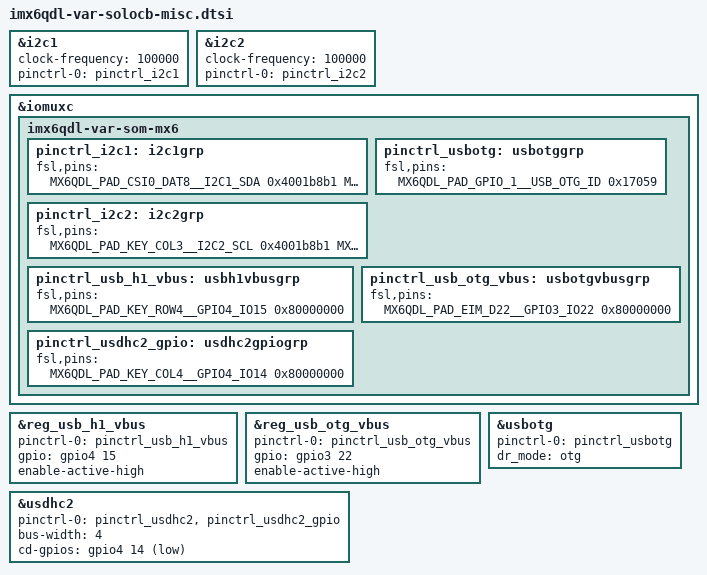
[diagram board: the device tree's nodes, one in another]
/*
 * Copyright (C) 2015-2024 Variscite Ltd.
 *
 * This program is free software; you can redistribute it and/or modify
 * it under the terms of the GNU General Public License version 2 as
 * published by the Free Software Foundation.
 *
 * Settings for VAR-SoloCustomBoard
 */

&i2c1 {
	clock-frequency = <100000>;
	pinctrl-names = "default";
	pinctrl-0 = <&pinctrl_i2c1>;
	status = "okay";
};

&i2c2 {
	clock-frequency = <100000>;
	pinctrl-names = "default";
	pinctrl-0 = <&pinctrl_i2c2>;
	status = "okay";
};

&iomuxc {
	imx6qdl-var-som-mx6 {
		pinctrl_i2c1: i2c1grp {
			fsl,pins = <
				MX6QDL_PAD_CSI0_DAT8__I2C1_SDA		0x4001b8b1
				MX6QDL_PAD_CSI0_DAT9__I2C1_SCL		0x4001b8b1
			>;
		};

		pinctrl_i2c2: i2c2grp {
			fsl,pins = <
				MX6QDL_PAD_KEY_COL3__I2C2_SCL		0x4001b8b1
				MX6QDL_PAD_KEY_ROW3__I2C2_SDA		0x4001b8b1
			>;
		};

		pinctrl_usbotg: usbotggrp {
			fsl,pins = <
				MX6QDL_PAD_GPIO_1__USB_OTG_ID		0x17059
			>;
		};

		pinctrl_usb_h1_vbus: usbh1vbusgrp {
			fsl,pins = <
				MX6QDL_PAD_KEY_ROW4__GPIO4_IO15		0x80000000
			>;
		};

		pinctrl_usb_otg_vbus: usbotgvbusgrp {
			fsl,pins = <
				MX6QDL_PAD_EIM_D22__GPIO3_IO22		0x80000000
			>;
		};

		pinctrl_usdhc2_gpio: usdhc2gpiogrp {
			fsl,pins = <
				/* SDMMC2 CD */
				MX6QDL_PAD_KEY_COL4__GPIO4_IO14		0x80000000
			>;
		};
	};
};

&reg_usb_h1_vbus {
	pinctrl-names = "default";
	pinctrl-0 = <&pinctrl_usb_h1_vbus>;
	gpio = <&gpio4 15 GPIO_ACTIVE_HIGH>;
	enable-active-high;
};

&reg_usb_otg_vbus {
	pinctrl-names = "default";
	pinctrl-0 = <&pinctrl_usb_otg_vbus>;
	gpio = <&gpio3 22 GPIO_ACTIVE_HIGH>;
	enable-active-high;
};

&usbotg {
	pinctrl-names = "default";
	pinctrl-0 = <&pinctrl_usbotg>;
	dr_mode = "otg"; /* Use "host" if you would like to use the USB0 type A connector */
};

&usdhc2 {	/* uSDHC2, MMC/SD card */
	pinctrl-names = "default";
	pinctrl-0 = <&pinctrl_usdhc2>, <&pinctrl_usdhc2_gpio>;
	bus-width = <4>;
	cd-gpios = <&gpio4 14 GPIO_ACTIVE_LOW>;
	status = "okay";
};
